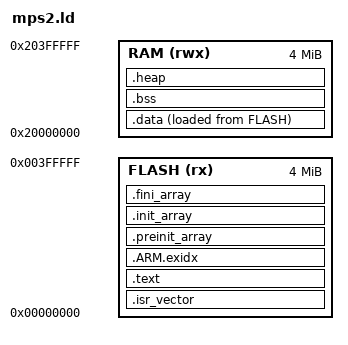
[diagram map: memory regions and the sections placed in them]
MEMORY
{
    FLASH (rx)  : ORIGIN = 0x00000000, LENGTH = 4M
    RAM   (rwx) : ORIGIN = 0x20000000, LENGTH = 4M
}

_estack = ORIGIN(RAM) + LENGTH(RAM);

ENTRY(Reset_Handler)

SECTIONS
{
    .isr_vector :
    {
        . = ALIGN(4);
        KEEP(*(.isr_vector))
        . = ALIGN(4);
    } > FLASH

    .text :
    {
        . = ALIGN(4);
        *(.text*)
        *(.rodata*)
        . = ALIGN(4);
    } > FLASH

    .ARM.exidx :
    {
        *(.ARM.exidx* .gnu.linkonce.armexidx.*)
    } > FLASH

    .preinit_array :
    {
        . = ALIGN(4);
        PROVIDE_HIDDEN(__preinit_array_start = .);
        KEEP(*(.preinit_array*))
        PROVIDE_HIDDEN(__preinit_array_end = .);
    } > FLASH

    .init_array :
    {
        . = ALIGN(4);
        PROVIDE_HIDDEN(__init_array_start = .);
        KEEP(*(SORT(.init_array.*)))
        KEEP(*(.init_array*))
        PROVIDE_HIDDEN(__init_array_end = .);
    } > FLASH

    .fini_array :
    {
        . = ALIGN(4);
        PROVIDE_HIDDEN(__fini_array_start = .);
        KEEP(*(SORT(.fini_array.*)))
        KEEP(*(.fini_array*))
        PROVIDE_HIDDEN(__fini_array_end = .);
    } > FLASH

    _sidata = LOADADDR(.data);

    .data :
    {
        . = ALIGN(4);
        _sdata = .;
        *(.data*)
        . = ALIGN(4);
        _edata = .;
    } > RAM AT > FLASH

    .bss :
    {
        . = ALIGN(4);
        _sbss = .;
        *(.bss*)
        *(COMMON)
        . = ALIGN(4);
        _ebss = .;
        _end = .;
        PROVIDE(end = _end);
    } > RAM

    .heap (NOLOAD) :
    {
        . = ALIGN(8);
        _heap_start = .;
        . += 256K;
        _heap_end = .;
    } > RAM

    ASSERT(__init_array_end > __init_array_start, "mps2.ld: .init_array is empty, test registrations were discarded")
}
